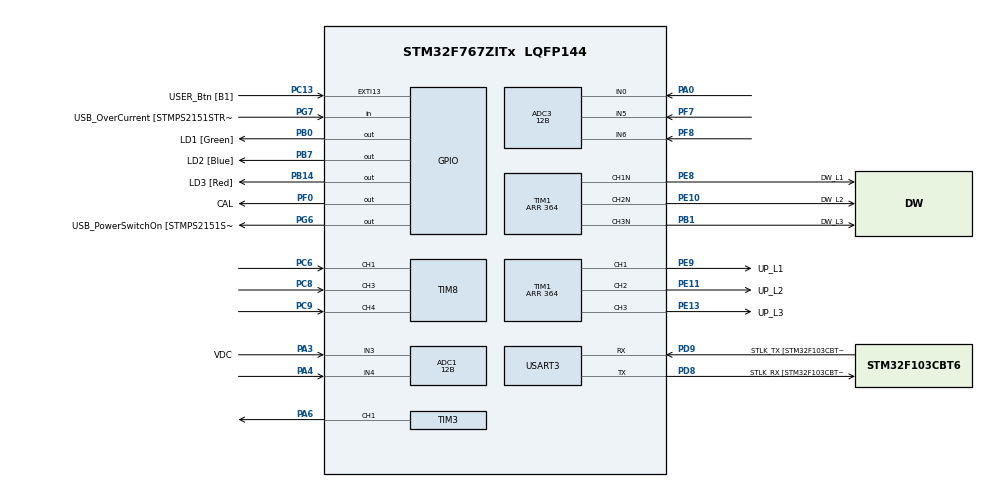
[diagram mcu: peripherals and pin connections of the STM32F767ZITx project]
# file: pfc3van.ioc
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ADC1.Channel-0\#ChannelRegularConversion=ADC_CHANNEL_3
ADC1.Channel-1\#ChannelRegularConversion=ADC_CHANNEL_4
ADC1.ClockPrescaler=ADC_CLOCK_SYNC_PCLK_DIV6
ADC1.ContinuousConvMode=ENABLE
ADC1.DMAContinuousRequests=ENABLE
ADC1.EOCSelection=ADC_EOC_SEQ_CONV
ADC1.EnableAnalogWatchDog=false
ADC1.ExternalTrigConv=ADC_SOFTWARE_START
ADC1.NbrOfConversion=2
ADC1.NbrOfConversionFlag=1
ADC1.Rank-0\#ChannelRegularConversion=1
ADC1.Rank-1\#ChannelRegularConversion=2
ADC1.Resolution=ADC_RESOLUTION_12B
ADC1.SamplingTime-0\#ChannelRegularConversion=ADC_SAMPLETIME_480CYCLES
ADC1.SamplingTime-1\#ChannelRegularConversion=ADC_SAMPLETIME_480CYCLES
ADC1.ScanConvMode=ADC_SCAN_ENABLE
ADC1.master=1
ADC3.Channel-1\#ChannelRegularConversion=ADC_CHANNEL_0
ADC3.Channel-10\#ChannelRegularConversion=ADC_CHANNEL_6
ADC3.Channel-9\#ChannelRegularConversion=ADC_CHANNEL_5
ADC3.ClockPrescaler=ADC_CLOCK_SYNC_PCLK_DIV6
ADC3.ContinuousConvMode=ENABLE
ADC3.DMAContinuousRequests=ENABLE
ADC3.DiscontinuousConvMode=DISABLE
ADC3.EOCSelection=ADC_EOC_SINGLE_CONV
ADC3.EnableAnalogWatchDog=false
ADC3.ExternalTrigConv=ADC_SOFTWARE_START
ADC3.NbrOfConversion=3
ADC3.NbrOfConversionFlag=1
ADC3.Rank-1\#ChannelRegularConversion=1
ADC3.Rank-10\#ChannelRegularConversion=3
ADC3.Rank-9\#ChannelRegularConversion=2
ADC3.Resolution=ADC_RESOLUTION_12B
ADC3.SamplingTime-1\#ChannelRegularConversion=ADC_SAMPLETIME_144CYCLES
ADC3.SamplingTime-10\#ChannelRegularConversion=ADC_SAMPLETIME_144CYCLES
ADC3.SamplingTime-9\#ChannelRegularConversion=ADC_SAMPLETIME_144CYCLES
ADC3.ScanConvMode=ADC_SCAN_ENABLE
CORTEX_M7.CPU_DCache=Enabled
CORTEX_M7.CPU_ICache=Enabled
CORTEX_M7.FlashInterface=TCM_Enabled
Dma.ADC1.1.Direction=DMA_PERIPH_TO_MEMORY
Dma.ADC1.1.FIFOMode=DMA_FIFOMODE_DISABLE
Dma.ADC1.1.Instance=DMA2_Stream0
Dma.ADC1.1.MemDataAlignment=DMA_MDATAALIGN_WORD
Dma.ADC1.1.MemInc=DMA_MINC_ENABLE
Dma.ADC1.1.Mode=DMA_CIRCULAR
Dma.ADC1.1.PeriphDataAlignment=DMA_PDATAALIGN_WORD
Dma.ADC1.1.PeriphInc=DMA_PINC_DISABLE
Dma.ADC1.1.Priority=DMA_PRIORITY_MEDIUM
Dma.ADC3.0.Direction=DMA_PERIPH_TO_MEMORY
Dma.ADC3.0.FIFOMode=DMA_FIFOMODE_DISABLE
Dma.ADC3.0.Instance=DMA2_Stream1
Dma.ADC3.0.MemDataAlignment=DMA_MDATAALIGN_WORD
Dma.ADC3.0.MemInc=DMA_MINC_ENABLE
Dma.ADC3.0.Mode=DMA_CIRCULAR
Dma.ADC3.0.PeriphDataAlignment=DMA_PDATAALIGN_WORD
Dma.ADC3.0.PeriphInc=DMA_PINC_DISABLE
Dma.ADC3.0.Priority=DMA_PRIORITY_VERY_HIGH
Dma.Request0=ADC3
Dma.Request1=ADC1
Dma.Request2=TIM8_CH1
Dma.Request3=TIM8_CH2
Dma.Request4=TIM8_CH3
Dma.Request5=TIM8_CH4/TRIG/COM
Dma.TIM8_CH1.2.Direction=DMA_PERIPH_TO_MEMORY
Dma.TIM8_CH1.2.FIFOMode=DMA_FIFOMODE_DISABLE
Dma.TIM8_CH1.2.Instance=DMA2_Stream2
Dma.TIM8_CH1.2.MemDataAlignment=DMA_MDATAALIGN_HALFWORD
Dma.TIM8_CH1.2.MemInc=DMA_MINC_ENABLE
Dma.TIM8_CH1.2.Mode=DMA_CIRCULAR
Dma.TIM8_CH1.2.PeriphDataAlignment=DMA_PDATAALIGN_HALFWORD
Dma.TIM8_CH1.2.PeriphInc=DMA_PINC_DISABLE
Dma.TIM8_CH1.2.Priority=DMA_PRIORITY_HIGH
Dma.TIM8_CH2.3.Direction=DMA_PERIPH_TO_MEMORY
Dma.TIM8_CH2.3.FIFOMode=DMA_FIFOMODE_DISABLE
Dma.TIM8_CH2.3.Instance=DMA2_Stream3
Dma.TIM8_CH2.3.MemDataAlignment=DMA_MDATAALIGN_HALFWORD
Dma.TIM8_CH2.3.MemInc=DMA_MINC_ENABLE
Dma.TIM8_CH2.3.Mode=DMA_CIRCULAR
Dma.TIM8_CH2.3.PeriphDataAlignment=DMA_PDATAALIGN_HALFWORD
Dma.TIM8_CH2.3.PeriphInc=DMA_PINC_DISABLE
Dma.TIM8_CH2.3.Priority=DMA_PRIORITY_HIGH
Dma.TIM8_CH3.4.Direction=DMA_PERIPH_TO_MEMORY
Dma.TIM8_CH3.4.FIFOMode=DMA_FIFOMODE_DISABLE
Dma.TIM8_CH3.4.Instance=DMA2_Stream4
Dma.TIM8_CH3.4.MemDataAlignment=DMA_MDATAALIGN_HALFWORD
Dma.TIM8_CH3.4.MemInc=DMA_MINC_ENABLE
Dma.TIM8_CH3.4.Mode=DMA_CIRCULAR
Dma.TIM8_CH3.4.PeriphDataAlignment=DMA_PDATAALIGN_HALFWORD
Dma.TIM8_CH3.4.PeriphInc=DMA_PINC_DISABLE
Dma.TIM8_CH3.4.Priority=DMA_PRIORITY_HIGH
Dma.TIM8_CH4/TRIG/COM.5.Direction=DMA_PERIPH_TO_MEMORY
Dma.TIM8_CH4/TRIG/COM.5.FIFOMode=DMA_FIFOMODE_DISABLE
Dma.TIM8_CH4/TRIG/COM.5.Instance=DMA2_Stream7
Dma.TIM8_CH4/TRIG/COM.5.MemDataAlignment=DMA_MDATAALIGN_HALFWORD
Dma.TIM8_CH4/TRIG/COM.5.MemInc=DMA_MINC_ENABLE
Dma.TIM8_CH4/TRIG/COM.5.Mode=DMA_CIRCULAR
Dma.TIM8_CH4/TRIG/COM.5.PeriphDataAlignment=DMA_PDATAALIGN_HALFWORD
Dma.TIM8_CH4/TRIG/COM.5.PeriphInc=DMA_PINC_DISABLE
Dma.TIM8_CH4/TRIG/COM.5.Priority=DMA_PRIORITY_HIGH
Mcu.Family=STM32F7
Mcu.Name=STM32F767ZITx
Mcu.Package=LQFP144
NVIC.DMA2_Stream0_IRQn=true\:6\:0\:true\:false\:true\:false\:true\:true
NVIC.DMA2_Stream1_IRQn=true\:6\:0\:false\:false\:true\:false\:true\:true
NVIC.DMA2_Stream2_IRQn=true\:6\:0\:true\:false\:true\:false\:true\:true
NVIC.DMA2_Stream3_IRQn=true\:6\:0\:true\:false\:true\:false\:true\:true
NVIC.DMA2_Stream4_IRQn=true\:6\:0\:true\:false\:true\:false\:true\:true
NVIC.DMA2_Stream7_IRQn=true\:6\:0\:true\:false\:true\:false\:true\:true
NVIC.EXTI15_10_IRQn=true\:15\:0\:true\:false\:true\:true\:true\:true
NVIC.PriorityGroup=NVIC_PRIORITYGROUP_4
NVIC.TIM1_CC_IRQn=true\:0\:0\:true\:false\:true\:true\:true\:true
NVIC.TIM1_TRG_COM_TIM11_IRQn=true\:0\:0\:false\:false\:true\:true\:true\:true
NVIC.TIM2_IRQn=true\:1\:0\:true\:false\:true\:true\:true\:true
NVIC.TIM5_IRQn=true\:15\:0\:true\:false\:true\:true\:true\:true
PA0/WKUP.Signal=ADCx_IN0
PA1.GPIO_Label=RMII_REF_CLK [LAN8742A-CZ-TR_REFCLK0]
PA1.Signal=ETH_REF_CLK
PA10.GPIO_Label=USB_ID
PA10.Signal=USB_OTG_FS_ID
PA11.GPIO_Label=USB_DM
PA11.Signal=USB_OTG_FS_DM
PA12.GPIO_Label=USB_DP
PA12.Signal=USB_OTG_FS_DP
PA13.GPIO_Label=TMS
PA13.Mode=Serial_Wire
PA13.Signal=SYS_JTMS-SWDIO
PA14.GPIO_Label=TCK
PA14.Mode=Serial_Wire
PA14.Signal=SYS_JTCK-SWCLK
PA2.GPIO_Label=RMII_MDIO [LAN8742A-CZ-TR_MDIO]
PA2.Signal=ETH_MDIO
PA3.GPIO_Label=VDC
PA3.Signal=ADCx_IN3
PA4.Signal=ADCx_IN4
PA6.Signal=S_TIM3_CH1
PA7.GPIO_Label=RMII_CRS_DV [LAN8742A-CZ-TR_CRS_DV]
PA7.Signal=ETH_CRS_DV
PA8.GPIO_Label=USB_SOF [TP1]
PA8.Signal=USB_OTG_FS_SOF
PA9.GPIO_Label=USB_VBUS
PA9.Signal=USB_OTG_FS_VBUS
PB0.GPIO_Label=LD1 [Green]
PB0.Signal=GPIO_Output
PB1.GPIO_Label=DW_L3
PB1.GPIO_PuPd=GPIO_PULLDOWN
PB1.GPIO_Speed=GPIO_SPEED_FREQ_HIGH
PB1.Mode=PWM Generation3 CH3 CH3N
PB1.Signal=TIM1_CH3N
PB13.GPIO_Label=RMII_TXD1 [LAN8742A-CZ-TR_TXD1]
PB13.Signal=ETH_TXD1
PB14.GPIO_Label=LD3 [Red]
PB14.Signal=GPIO_Output
PB3.GPIO_Label=SWO
PB3.Signal=SYS_JTDO-SWO
PB7.GPIO_Label=LD2 [Blue]
PB7.Signal=GPIO_Output
PC1.GPIO_Label=RMII_MDC [LAN8742A-CZ-TR_MDC]
PC1.Signal=ETH_MDC
PC13.GPIO_Label=USER_Btn [B1]
PC13.Signal=GPXTI13
PC14/OSC32_IN.Mode=LSE-External-Oscillator
PC14/OSC32_IN.Signal=RCC_OSC32_IN
PC15/OSC32_OUT.Mode=LSE-External-Oscillator
PC15/OSC32_OUT.Signal=RCC_OSC32_OUT
PC4.GPIO_Label=RMII_RXD0 [LAN8742A-CZ-TR_RXD0]
PC4.Signal=ETH_RXD0
PC5.GPIO_Label=RMII_RXD1 [LAN8742A-CZ-TR_RXD1]
PC5.Signal=ETH_RXD1
PC6.GPIO_Speed=GPIO_SPEED_FREQ_VERY_HIGH
PC6.Signal=S_TIM8_CH1
PC8.GPIO_Speed=GPIO_SPEED_FREQ_VERY_HIGH
PC8.Signal=S_TIM8_CH3
PC9.GPIO_Speed=GPIO_SPEED_FREQ_VERY_HIGH
PC9.Signal=S_TIM8_CH4
PD8.GPIO_Label=STLK_RX [STM32F103CBT6_PA3]
PD8.Mode=Asynchronous
PD8.Signal=USART3_TX
PD9.GPIO_Label=STLK_TX [STM32F103CBT6_PA2]
PD9.Mode=Asynchronous
PD9.Signal=USART3_RX
PE10.GPIO_Label=DW_L2
PE10.GPIO_ModeDefaultPP=GPIO_MODE_AF_PP
PE10.GPIO_PuPd=GPIO_PULLDOWN
PE10.GPIO_Speed=GPIO_SPEED_FREQ_HIGH
PE10.Mode=PWM Generation2 CH2 CH2N
PE10.Signal=TIM1_CH2N
PE11.GPIO_Label=UP_L2
PE11.GPIO_ModeDefaultPP=GPIO_MODE_AF_PP
PE11.GPIO_PuPd=GPIO_PULLDOWN
PE11.GPIO_Speed=GPIO_SPEED_FREQ_HIGH
PE11.Signal=S_TIM1_CH2
PE13.GPIO_Label=UP_L3
PE13.GPIO_ModeDefaultPP=GPIO_MODE_AF_PP
PE13.GPIO_PuPd=GPIO_PULLDOWN
PE13.GPIO_Speed=GPIO_SPEED_FREQ_HIGH
PE13.Signal=S_TIM1_CH3
PE8.GPIO_Label=DW_L1
PE8.GPIO_ModeDefaultPP=GPIO_MODE_AF_PP
PE8.GPIO_PuPd=GPIO_PULLDOWN
PE8.GPIO_Speed=GPIO_SPEED_FREQ_HIGH
PE8.Mode=PWM Generation1 CH1 CH1N
PE8.Signal=TIM1_CH1N
PE9.GPIO_Label=UP_L1
PE9.GPIO_ModeDefaultPP=GPIO_MODE_AF_PP
PE9.GPIO_PuPd=GPIO_PULLDOWN
PE9.GPIO_Speed=GPIO_SPEED_FREQ_HIGH
PE9.Signal=S_TIM1_CH1
PF0.GPIO_Label=CAL
PF0.GPIO_Speed=GPIO_SPEED_FREQ_VERY_HIGH
PF0.PinState=GPIO_PIN_RESET
PF0.Signal=GPIO_Output
PF7.Mode=IN5
PF7.Signal=ADC3_IN5
PF8.Mode=IN6
PF8.Signal=ADC3_IN6
PG11.GPIO_Label=RMII_TX_EN [LAN8742A-CZ-TR_TXEN]
PG11.Signal=ETH_TX_EN
PG13.GPIO_Label=RMII_TXD0 [LAN8742A-CZ-TR_TXD0]
PG13.Signal=ETH_TXD0
PG6.GPIO_Label=USB_PowerSwitchOn [STMPS2151STR_EN]
PG6.Signal=GPIO_Output
PG7.GPIO_Label=USB_OverCurrent [STMPS2151STR_FAULT]
PG7.Signal=GPIO_Input
PH0/OSC_IN.GPIO_Label=MCO [STM32F103CBT6_PA8]
PH0/OSC_IN.Mode=HSE-External-Clock-Source
PH0/OSC_IN.Signal=RCC_OSC_IN
PH1/OSC_OUT.Mode=HSE-External-Clock-Source
PH1/OSC_OUT.Signal=RCC_OSC_OUT
ProjectManager.HeapSize=0x200
ProjectManager.StackSize=0x400
ProjectManager.TargetToolchain=CMake
RCC.48MHZClocksFreq_Value=24000000
RCC.AHBFreq_Value=192000000
RCC.APB1CLKDivider=RCC_HCLK_DIV4
RCC.APB1Freq_Value=48000000
RCC.APB1TimFreq_Value=96000000
RCC.APB2CLKDivider=RCC_HCLK_DIV2
RCC.APB2Freq_Value=96000000
RCC.APB2TimFreq_Value=192000000
RCC.CortexFreq_Value=192000000
RCC.HCLKFreq_Value=192000000
RCC.HSE_VALUE=32000000
RCC.HSI_VALUE=16000000
RCC.PLLMUL=RCC_PLL_MUL9
RCC.PLLQ=4
RCC.PLLSourceVirtual=RCC_PLLSOURCE_HSE
RCC.PRESCALERUSB=RCC_USBCLKSOURCE_PLL_DIV1_5
RCC.SYSCLKFreq_VALUE=192000000
RCC.SYSCLKSource=RCC_SYSCLKSOURCE_PLLCLK
RCC.SYSCLKSourceVirtual=RCC_SYSCLKSOURCE_PLLCLK
RCC.USBFreq_Value=96000000
RCC.VCOOutputFreq_Value=384000000
SH.ADCx_IN0.0=ADC3_IN0,IN0
SH.ADCx_IN3.0=ADC1_IN3,IN3
SH.ADCx_IN4.0=ADC1_IN4,IN4
SH.S_TIM1_CH1.0=TIM1_CH1,PWM Generation1 CH1 CH1N
SH.S_TIM1_CH2.0=TIM1_CH2,PWM Generation2 CH2 CH2N
SH.S_TIM1_CH3.0=TIM1_CH3,PWM Generation3 CH3 CH3N
SH.S_TIM3_CH1.0=TIM3_CH1,Forced Output1 CH1
SH.S_TIM8_CH1.0=TIM8_CH1,Input_Capture1_from_TI1
SH.S_TIM8_CH1.1=TIM8_CH1,TriggerSource_TI1FP1
SH.S_TIM8_CH3.0=TIM8_CH3,Input_Capture3_from_TI3
SH.S_TIM8_CH4.0=TIM8_CH4,Input_Capture4_from_TI4
TIM1.AutoReloadPreload=TIM_AUTORELOAD_PRELOAD_ENABLE
TIM1.AutomaticOutput=TIM_AUTOMATICOUTPUT_DISABLE
TIM1.Break2State=TIM_BREAK2_ENABLE
TIM1.BreakState=TIM_BREAK_DISABLE
TIM1.Channel-PWM\ Generation1\ CH1\ CH1N=TIM_CHANNEL_1
TIM1.Channel-PWM\ Generation2\ CH2\ CH2N=TIM_CHANNEL_2
TIM1.Channel-PWM\ Generation3\ CH3\ CH3N=TIM_CHANNEL_3
TIM1.CounterMode=TIM_COUNTERMODE_CENTERALIGNED1
TIM1.DeadTime=19
TIM1.OCFastMode_PWM-PWM\ Generation1\ CH1\ CH1N=TIM_OCFAST_DISABLE
TIM1.OCIdleState_1=TIM_OCIDLESTATE_RESET
TIM1.OCMode_PWM-PWM\ Generation1\ CH1\ CH1N=TIM_OCMODE_PWM2
TIM1.OCMode_PWM-PWM\ Generation2\ CH2\ CH2N=TIM_OCMODE_PWM2
TIM1.OCMode_PWM-PWM\ Generation3\ CH3\ CH3N=TIM_OCMODE_PWM2
TIM1.OCNIdleState_1=TIM_OCNIDLESTATE_RESET
TIM1.OCNIdleState_2=TIM_OCNIDLESTATE_RESET
TIM1.OCNPolarity_1=TIM_OCNPOLARITY_HIGH
TIM1.OCNPolarity_2=TIM_OCNPOLARITY_HIGH
TIM1.OCPolarity_1=TIM_OCPOLARITY_HIGH
TIM1.OffStateIDLEMode=TIM_OSSI_ENABLE
TIM1.OffStateRunMode=TIM_OSSR_ENABLE
TIM1.Period=364
TIM1.Pulse-PWM\ Generation1\ CH1\ CH1N=300
TIM1.Pulse-PWM\ Generation2\ CH2\ CH2N=600
TIM1.Pulse-PWM\ Generation3\ CH3\ CH3N=200
TIM1.RepetitionCounter=0
TIM1.TIM_MasterOutputTrigger=TIM_TRGO_UPDATE
TIM1.TIM_MasterOutputTrigger2=TIM_TRGO2_RESET
TIM1.TIM_MasterSlaveMode=TIM_MASTERSLAVEMODE_DISABLE
TIM11.Period=65535
TIM2.Period=3000
TIM3.Channel-Forced\ Output1\ CH1=TIM_CHANNEL_1
TIM3.TIM_MasterOutputTrigger=TIM_TRGO_ENABLE
TIM3.TIM_MasterSlaveMode=TIM_MASTERSLAVEMODE_ENABLE
TIM5.Period=4294967295
TIM8.Channel-Input_Capture1_from_TI1=TIM_CHANNEL_1
TIM8.Channel-Input_Capture2_from_TI1_63=TIM_CHANNEL_2
TIM8.Channel-Input_Capture3_from_TI3=TIM_CHANNEL_3
TIM8.Channel-Input_Capture4_from_TI4=TIM_CHANNEL_4
TIM8.ICFilter_CH1=10
TIM8.ICFilter_CH3=10
TIM8.ICFilter_CH4=10
TIM8.ICPolarity_CH1=TIM_INPUTCHANNELPOLARITY_RISING
TIM8.ICPolarity_CH2=TIM_INPUTCHANNELPOLARITY_FALLING
TIM8.ICPolarity_CH3=TIM_INPUTCHANNELPOLARITY_FALLING
TIM8.ICPolarity_CH4=TIM_INPUTCHANNELPOLARITY_FALLING
USART3.VirtualMode-Asynchronous=VM_ASYNC
VP_TIM11_VS_ClockSourceINT.Mode=Enable_Timer
VP_TIM1_VS_ClockSourceINT.Mode=Internal
VP_TIM2_VS_ClockSourceINT.Mode=Internal
VP_TIM3_VS_ClockSourceINT.Mode=Internal
VP_TIM5_VS_ClockSourceINT.Mode=Internal
VP_TIM8_VS_ClockSourceINT.Mode=Internal
VP_TIM8_VS_ControllerModeReset.Mode=Reset Mode
VP_TIM8_VS_indirect_ch1.Mode=Input_Capture2_from_TI1_63
board=NUCLEO-F767ZI

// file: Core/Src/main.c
/* USER CODE BEGIN Header */
/**
 ******************************************************************************
 * @file           : main.c
 * @brief          : Main program body
 ******************************************************************************
 * @attention
 *
 * Copyright (c) 2025 STMicroelectronics.
 * All rights reserved.
 *
 * This software is licensed under terms that can be found in the LICENSE file
 * in the root directory of this software component.
 * If no LICENSE file comes with this software, it is provided AS-IS.
 *
 ******************************************************************************
 */
/* USER CODE END Header */
#include "main.h"

/* USER CODE BEGIN PV */
#define CTRL_ON 1
#define CTRL_OFF 0
#define VAC_LENGTH 1
int8_t CTRL_STATE = CTRL_OFF;

/* USER CODE END PV */

void SystemClock_Config(void);
static void MX_GPIO_Init(void);
static void MX_DMA_Init(void);
static void MX_ADC3_Init(void);
static void MX_USART3_UART_Init(void);
static void MX_ADC1_Init(void);
static void MX_TIM1_Init(void);
static void MX_TIM3_Init(void);
static void MX_TIM2_Init(void);
static void MX_TIM11_Init(void);
static void MX_TIM8_Init(void);
static void MX_TIM5_Init(void);

/* USER CODE BEGIN 0 */
static void Init_Ctrl(void);
uint32_t iac_data[3], dc_data[2], vac_data[1], vac_1_data[1];
uint32_t vacs[4];
/* USER CODE END 0 */

int main(void) {

  /* Enable the CPU Cache */

  /* Enable I-Cache---------------------------------------------------------*/
  SCB_EnableICache();

  /* Enable D-Cache---------------------------------------------------------*/
  SCB_EnableDCache();

  /* MCU Configuration--------------------------------------------------------*/

  /* Reset of all peripherals, Initializes the Flash interface and the Systick.
   */
  LL_APB1_GRP1_EnableClock(LL_APB1_GRP1_PERIPH_PWR);
  LL_APB2_GRP1_EnableClock(LL_APB2_GRP1_PERIPH_SYSCFG);

  /* System interrupt init*/
  NVIC_SetPriorityGrouping(NVIC_PRIORITYGROUP_4);

  /* MemoryManagement_IRQn interrupt configuration */
  NVIC_SetPriority(MemoryManagement_IRQn,
                   NVIC_EncodePriority(NVIC_GetPriorityGrouping(), 4, 0));
  /* BusFault_IRQn interrupt configuration */
  NVIC_SetPriority(BusFault_IRQn,
                   NVIC_EncodePriority(NVIC_GetPriorityGrouping(), 4, 0));
  /* UsageFault_IRQn interrupt configuration */
  NVIC_SetPriority(UsageFault_IRQn,
                   NVIC_EncodePriority(NVIC_GetPriorityGrouping(), 4, 0));
  /* SVCall_IRQn interrupt configuration */
  NVIC_SetPriority(SVCall_IRQn,
                   NVIC_EncodePriority(NVIC_GetPriorityGrouping(), 4, 0));
  /* DebugMonitor_IRQn interrupt configuration */
  NVIC_SetPriority(DebugMonitor_IRQn,
                   NVIC_EncodePriority(NVIC_GetPriorityGrouping(), 4, 0));
  /* PendSV_IRQn interrupt configuration */
  NVIC_SetPriority(PendSV_IRQn,
                   NVIC_EncodePriority(NVIC_GetPriorityGrouping(), 4, 0));

  /* Configure the system clock */
  SystemClock_Config();

  /* Initialize all configured peripherals */
  MX_GPIO_Init();
  MX_DMA_Init();
  MX_ADC3_Init();
  MX_USART3_UART_Init();
  MX_ADC1_Init();
  MX_TIM1_Init();
  MX_TIM3_Init();
  MX_TIM2_Init();
  MX_TIM11_Init();
  MX_TIM8_Init();
  MX_TIM5_Init();
  /* USER CODE BEGIN 2 */
  Init_Ctrl();

  /* USER CODE END 2 */

  /* Infinite loop */
  while (1) {

  }
}

void SystemClock_Config(void) {
  LL_FLASH_SetLatency(LL_FLASH_LATENCY_6);
  while (LL_FLASH_GetLatency() != LL_FLASH_LATENCY_6) {
  }
  LL_PWR_SetRegulVoltageScaling(LL_PWR_REGU_VOLTAGE_SCALE1);
  LL_PWR_EnableOverDriveMode();
  LL_RCC_HSE_EnableBypass();
  LL_RCC_HSE_Enable();

  /* Wait till HSE is ready */
  while (LL_RCC_HSE_IsReady() != 1) {
  }
  LL_RCC_PLL_ConfigDomain_SYS(LL_RCC_PLLSOURCE_HSE, LL_RCC_PLLM_DIV_16, 192,
                              LL_RCC_PLLP_DIV_2);
  LL_RCC_PLL_Enable();

  /* Wait till PLL is ready */
  while (LL_RCC_PLL_IsReady() != 1) {
  }
  while (LL_PWR_IsActiveFlag_VOS() == 0) {
  }
  LL_RCC_SetAHBPrescaler(LL_RCC_SYSCLK_DIV_1);
  LL_RCC_SetAPB1Prescaler(LL_RCC_APB1_DIV_4);
  LL_RCC_SetAPB2Prescaler(LL_RCC_APB2_DIV_2);
  LL_RCC_SetSysClkSource(LL_RCC_SYS_CLKSOURCE_PLL);

  /* Wait till System clock is ready */
  while (LL_RCC_GetSysClkSource() != LL_RCC_SYS_CLKSOURCE_STATUS_PLL) {
  }
  LL_Init1msTick(192000000);
  LL_SetSystemCoreClock(192000000);

  /* Set Timers Clock Prescalers */
  LL_RCC_SetTIMPrescaler(LL_RCC_TIM_PRESCALER_TWICE);
}

static void MX_ADC1_Init(void) {

  LL_ADC_InitTypeDef ADC_InitStruct = {0};
  LL_ADC_REG_InitTypeDef ADC_REG_InitStruct = {0};
  LL_ADC_CommonInitTypeDef ADC_CommonInitStruct = {0};

  LL_GPIO_InitTypeDef GPIO_InitStruct = {0};

  /* Peripheral clock enable */
  LL_APB2_GRP1_EnableClock(LL_APB2_GRP1_PERIPH_ADC1);

  LL_AHB1_GRP1_EnableClock(LL_AHB1_GRP1_PERIPH_GPIOA);
  /**ADC1 GPIO Configuration
  PA3   ------> ADC1_IN3
  PA4   ------> ADC1_IN4
  */
  GPIO_InitStruct.Pin = VDC_Pin;
  GPIO_InitStruct.Mode = LL_GPIO_MODE_ANALOG;
  GPIO_InitStruct.Pull = LL_GPIO_PULL_NO;
  LL_GPIO_Init(VDC_GPIO_Port, &GPIO_InitStruct);

  GPIO_InitStruct.Pin = LL_GPIO_PIN_4;
  GPIO_InitStruct.Mode = LL_GPIO_MODE_ANALOG;
  GPIO_InitStruct.Pull = LL_GPIO_PULL_NO;
  LL_GPIO_Init(GPIOA, &GPIO_InitStruct);

  /* ADC1 DMA Init */

  /* ADC1 Init */
  LL_DMA_SetChannelSelection(DMA2, LL_DMA_STREAM_0, LL_DMA_CHANNEL_0);

  LL_DMA_SetDataTransferDirection(DMA2, LL_DMA_STREAM_0,
                                  LL_DMA_DIRECTION_PERIPH_TO_MEMORY);

  LL_DMA_SetStreamPriorityLevel(DMA2, LL_DMA_STREAM_0, LL_DMA_PRIORITY_MEDIUM);

  LL_DMA_SetMode(DMA2, LL_DMA_STREAM_0, LL_DMA_MODE_CIRCULAR);

  LL_DMA_SetPeriphIncMode(DMA2, LL_DMA_STREAM_0, LL_DMA_PERIPH_NOINCREMENT);

  LL_DMA_SetMemoryIncMode(DMA2, LL_DMA_STREAM_0, LL_DMA_MEMORY_INCREMENT);

  LL_DMA_SetPeriphSize(DMA2, LL_DMA_STREAM_0, LL_DMA_PDATAALIGN_WORD);

  LL_DMA_SetMemorySize(DMA2, LL_DMA_STREAM_0, LL_DMA_MDATAALIGN_WORD);

  LL_DMA_DisableFifoMode(DMA2, LL_DMA_STREAM_0);

  /** Common config
   */
  ADC_InitStruct.Resolution = LL_ADC_RESOLUTION_12B;
  ADC_InitStruct.DataAlignment = LL_ADC_DATA_ALIGN_RIGHT;
  ADC_InitStruct.SequencersScanMode = LL_ADC_SEQ_SCAN_ENABLE;
  LL_ADC_Init(ADC1, &ADC_InitStruct);
  ADC_REG_InitStruct.TriggerSource = LL_ADC_REG_TRIG_SOFTWARE;
  ADC_REG_InitStruct.SequencerLength = LL_ADC_REG_SEQ_SCAN_ENABLE_2RANKS;
  ADC_REG_InitStruct.SequencerDiscont = LL_ADC_REG_SEQ_DISCONT_DISABLE;
  ADC_REG_InitStruct.ContinuousMode = LL_ADC_REG_CONV_CONTINUOUS;
  ADC_REG_InitStruct.DMATransfer = LL_ADC_REG_DMA_TRANSFER_UNLIMITED;
  LL_ADC_REG_Init(ADC1, &ADC_REG_InitStruct);
  LL_ADC_REG_SetFlagEndOfConversion(ADC1, LL_ADC_REG_FLAG_EOC_SEQUENCE_CONV);
  ADC_CommonInitStruct.CommonClock = LL_ADC_CLOCK_SYNC_PCLK_DIV6;
  ADC_CommonInitStruct.Multimode = LL_ADC_MULTI_INDEPENDENT;
  LL_ADC_CommonInit(__LL_ADC_COMMON_INSTANCE(ADC1), &ADC_CommonInitStruct);

  /** Configure Regular Channel
   */
  LL_ADC_REG_SetSequencerRanks(ADC1, LL_ADC_REG_RANK_1, LL_ADC_CHANNEL_3);
  LL_ADC_SetChannelSamplingTime(ADC1, LL_ADC_CHANNEL_3,
                                LL_ADC_SAMPLINGTIME_480CYCLES);

  /** Configure Regular Channel
   */
  LL_ADC_REG_SetSequencerRanks(ADC1, LL_ADC_REG_RANK_2, LL_ADC_CHANNEL_4);
  LL_ADC_SetChannelSamplingTime(ADC1, LL_ADC_CHANNEL_4,
                                LL_ADC_SAMPLINGTIME_480CYCLES);
  /* USER CODE BEGIN ADC1_Init 2 */
  LL_DMA_ConfigAddresses(
      DMA2, LL_DMA_STREAM_0,
      LL_ADC_DMA_GetRegAddr(ADC1, LL_ADC_DMA_REG_REGULAR_DATA),
      (uint32_t)&dc_data, LL_DMA_DIRECTION_PERIPH_TO_MEMORY);
  LL_DMA_SetDataLength(DMA2, LL_DMA_STREAM_0, (uint32_t)2);

  /* Enable DMA transfer interruption: transfer complete */
  LL_DMA_EnableIT_TC(DMA2, LL_DMA_STREAM_0);

  /* Enable DMA transfer interruption: half transfer */

  /* Enable DMA transfer interruption: transfer error */
  LL_DMA_EnableIT_TE(DMA2, LL_DMA_STREAM_0);
  LL_DMA_EnableStream(DMA2, LL_DMA_STREAM_0);
  /* USER CODE END ADC1_Init 2 */
}

static void MX_ADC3_Init(void) {

  LL_ADC_InitTypeDef ADC_InitStruct = {0};
  LL_ADC_REG_InitTypeDef ADC_REG_InitStruct = {0};

  LL_GPIO_InitTypeDef GPIO_InitStruct = {0};

  /* Peripheral clock enable */
  LL_APB2_GRP1_EnableClock(LL_APB2_GRP1_PERIPH_ADC3);

  LL_AHB1_GRP1_EnableClock(LL_AHB1_GRP1_PERIPH_GPIOF);
  LL_AHB1_GRP1_EnableClock(LL_AHB1_GRP1_PERIPH_GPIOA);
  /**ADC3 GPIO Configuration
  PF7   ------> ADC3_IN5
  PF8   ------> ADC3_IN6
  PA0/WKUP   ------> ADC3_IN0
  */
  GPIO_InitStruct.Pin = LL_GPIO_PIN_7;
  GPIO_InitStruct.Mode = LL_GPIO_MODE_ANALOG;
  GPIO_InitStruct.Pull = LL_GPIO_PULL_NO;
  LL_GPIO_Init(GPIOF, &GPIO_InitStruct);

  GPIO_InitStruct.Pin = LL_GPIO_PIN_8;
  GPIO_InitStruct.Mode = LL_GPIO_MODE_ANALOG;
  GPIO_InitStruct.Pull = LL_GPIO_PULL_NO;
  LL_GPIO_Init(GPIOF, &GPIO_InitStruct);

  GPIO_InitStruct.Pin = LL_GPIO_PIN_0;
  GPIO_InitStruct.Mode = LL_GPIO_MODE_ANALOG;
  GPIO_InitStruct.Pull = LL_GPIO_PULL_NO;
  LL_GPIO_Init(GPIOA, &GPIO_InitStruct);

  /* ADC3 DMA Init */

  /* ADC3 Init */
  LL_DMA_SetChannelSelection(DMA2, LL_DMA_STREAM_1, LL_DMA_CHANNEL_2);

  LL_DMA_SetDataTransferDirection(DMA2, LL_DMA_STREAM_1,
                                  LL_DMA_DIRECTION_PERIPH_TO_MEMORY);

  LL_DMA_SetStreamPriorityLevel(DMA2, LL_DMA_STREAM_1,
                                LL_DMA_PRIORITY_VERYHIGH);

  LL_DMA_SetMode(DMA2, LL_DMA_STREAM_1, LL_DMA_MODE_CIRCULAR);

  LL_DMA_SetPeriphIncMode(DMA2, LL_DMA_STREAM_1, LL_DMA_PERIPH_NOINCREMENT);

  LL_DMA_SetMemoryIncMode(DMA2, LL_DMA_STREAM_1, LL_DMA_MEMORY_INCREMENT);

  LL_DMA_SetPeriphSize(DMA2, LL_DMA_STREAM_1, LL_DMA_PDATAALIGN_WORD);

  LL_DMA_SetMemorySize(DMA2, LL_DMA_STREAM_1, LL_DMA_MDATAALIGN_WORD);

  LL_DMA_DisableFifoMode(DMA2, LL_DMA_STREAM_1);

  /* USER CODE BEGIN ADC3_Init 1 */
  LL_DMA_ConfigAddresses(
      DMA2, LL_DMA_STREAM_1,
      LL_ADC_DMA_GetRegAddr(ADC3, LL_ADC_DMA_REG_REGULAR_DATA),
      (uint32_t)&iac_data, LL_DMA_DIRECTION_PERIPH_TO_MEMORY);
  LL_DMA_SetDataLength(DMA2, LL_DMA_STREAM_1, (uint32_t)3);

  /* Enable DMA transfer interruption: transfer complete */
  LL_DMA_EnableIT_TC(DMA2, LL_DMA_STREAM_1);

  /* Enable DMA transfer interruption: half transfer */

  /* Enable DMA transfer interruption: transfer error */
  LL_DMA_EnableIT_TE(DMA2, LL_DMA_STREAM_1);
  LL_DMA_EnableStream(DMA2, LL_DMA_STREAM_1);
  /* USER CODE END ADC3_Init 1 */

  /** Common config
   */
  ADC_InitStruct.Resolution = LL_ADC_RESOLUTION_12B;
  ADC_InitStruct.DataAlignment = LL_ADC_DATA_ALIGN_RIGHT;
  ADC_InitStruct.SequencersScanMode = LL_ADC_SEQ_SCAN_ENABLE;
  LL_ADC_Init(ADC3, &ADC_InitStruct);
  ADC_REG_InitStruct.TriggerSource = LL_ADC_REG_TRIG_SOFTWARE;
  ADC_REG_InitStruct.SequencerLength = LL_ADC_REG_SEQ_SCAN_ENABLE_3RANKS;
  ADC_REG_InitStruct.SequencerDiscont = LL_ADC_REG_SEQ_DISCONT_DISABLE;
  ADC_REG_InitStruct.ContinuousMode = LL_ADC_REG_CONV_CONTINUOUS;
  ADC_REG_InitStruct.DMATransfer = LL_ADC_REG_DMA_TRANSFER_UNLIMITED;
  LL_ADC_REG_Init(ADC3, &ADC_REG_InitStruct);
  LL_ADC_REG_SetFlagEndOfConversion(ADC3, LL_ADC_REG_FLAG_EOC_UNITARY_CONV);

  /** Configure Regular Channel
   */
  LL_ADC_REG_SetSequencerRanks(ADC3, LL_ADC_REG_RANK_1, LL_ADC_CHANNEL_0);
  LL_ADC_SetChannelSamplingTime(ADC3, LL_ADC_CHANNEL_0,
                                LL_ADC_SAMPLINGTIME_144CYCLES);

  /** Configure Regular Channel
   */
  LL_ADC_REG_SetSequencerRanks(ADC3, LL_ADC_REG_RANK_2, LL_ADC_CHANNEL_5);
  LL_ADC_SetChannelSamplingTime(ADC3, LL_ADC_CHANNEL_5,
                                LL_ADC_SAMPLINGTIME_144CYCLES);

  /** Configure Regular Channel
   */
  LL_ADC_REG_SetSequencerRanks(ADC3, LL_ADC_REG_RANK_3, LL_ADC_CHANNEL_6);
  LL_ADC_SetChannelSamplingTime(ADC3, LL_ADC_CHANNEL_6,
                                LL_ADC_SAMPLINGTIME_144CYCLES);
}

static void MX_TIM1_Init(void) {

  LL_TIM_InitTypeDef TIM_InitStruct = {0};
  LL_TIM_OC_InitTypeDef TIM_OC_InitStruct = {0};
  LL_TIM_BDTR_InitTypeDef TIM_BDTRInitStruct = {0};

  LL_GPIO_InitTypeDef GPIO_InitStruct = {0};

  /* Peripheral clock enable */
  LL_APB2_GRP1_EnableClock(LL_APB2_GRP1_PERIPH_TIM1);

  /* TIM1 interrupt Init */
  NVIC_SetPriority(TIM1_TRG_COM_TIM11_IRQn,
                   NVIC_EncodePriority(NVIC_GetPriorityGrouping(), 0, 0));
  NVIC_EnableIRQ(TIM1_TRG_COM_TIM11_IRQn);
  NVIC_SetPriority(TIM1_CC_IRQn,
                   NVIC_EncodePriority(NVIC_GetPriorityGrouping(), 0, 0));
  NVIC_EnableIRQ(TIM1_CC_IRQn);

  TIM_InitStruct.Prescaler = 0;
  TIM_InitStruct.CounterMode = LL_TIM_COUNTERMODE_CENTER_DOWN;
  TIM_InitStruct.Autoreload = 364;
  TIM_InitStruct.ClockDivision = LL_TIM_CLOCKDIVISION_DIV1;
  TIM_InitStruct.RepetitionCounter = 0;
  LL_TIM_Init(TIM1, &TIM_InitStruct);
  LL_TIM_EnableARRPreload(TIM1);
  LL_TIM_SetClockSource(TIM1, LL_TIM_CLOCKSOURCE_INTERNAL);
  LL_TIM_OC_EnablePreload(TIM1, LL_TIM_CHANNEL_CH1);
  TIM_OC_InitStruct.OCMode = LL_TIM_OCMODE_PWM2;
  TIM_OC_InitStruct.OCState = LL_TIM_OCSTATE_DISABLE;
  TIM_OC_InitStruct.OCNState = LL_TIM_OCSTATE_DISABLE;
  TIM_OC_InitStruct.CompareValue = 300;
  TIM_OC_InitStruct.OCPolarity = LL_TIM_OCPOLARITY_HIGH;
  TIM_OC_InitStruct.OCNPolarity = LL_TIM_OCPOLARITY_HIGH;
  TIM_OC_InitStruct.OCIdleState = LL_TIM_OCIDLESTATE_LOW;
  TIM_OC_InitStruct.OCNIdleState = LL_TIM_OCIDLESTATE_LOW;
  LL_TIM_OC_Init(TIM1, LL_TIM_CHANNEL_CH1, &TIM_OC_InitStruct);
  LL_TIM_OC_DisableFast(TIM1, LL_TIM_CHANNEL_CH1);
  LL_TIM_OC_EnablePreload(TIM1, LL_TIM_CHANNEL_CH2);
  TIM_OC_InitStruct.CompareValue = 600;
  LL_TIM_OC_Init(TIM1, LL_TIM_CHANNEL_CH2, &TIM_OC_InitStruct);
  LL_TIM_OC_DisableFast(TIM1, LL_TIM_CHANNEL_CH2);
  LL_TIM_OC_EnablePreload(TIM1, LL_TIM_CHANNEL_CH3);
  TIM_OC_InitStruct.CompareValue = 200;
  LL_TIM_OC_Init(TIM1, LL_TIM_CHANNEL_CH3, &TIM_OC_InitStruct);
  LL_TIM_OC_DisableFast(TIM1, LL_TIM_CHANNEL_CH3);
  LL_TIM_SetTriggerOutput(TIM1, LL_TIM_TRGO_UPDATE);
  LL_TIM_SetTriggerOutput2(TIM1, LL_TIM_TRGO2_RESET);
  LL_TIM_DisableMasterSlaveMode(TIM1);
  TIM_BDTRInitStruct.OSSRState = LL_TIM_OSSR_ENABLE;
  TIM_BDTRInitStruct.OSSIState = LL_TIM_OSSI_ENABLE;
  TIM_BDTRInitStruct.LockLevel = LL_TIM_LOCKLEVEL_OFF;
  TIM_BDTRInitStruct.DeadTime = 19;
  TIM_BDTRInitStruct.BreakState = LL_TIM_BREAK_DISABLE;
  TIM_BDTRInitStruct.BreakPolarity = LL_TIM_BREAK_POLARITY_HIGH;
  TIM_BDTRInitStruct.BreakFilter = LL_TIM_BREAK_FILTER_FDIV1;
  TIM_BDTRInitStruct.Break2State = LL_TIM_BREAK2_ENABLE;
  TIM_BDTRInitStruct.Break2Polarity = LL_TIM_BREAK2_POLARITY_HIGH;
  TIM_BDTRInitStruct.Break2Filter = LL_TIM_BREAK2_FILTER_FDIV1;
  TIM_BDTRInitStruct.AutomaticOutput = LL_TIM_AUTOMATICOUTPUT_DISABLE;
  LL_TIM_BDTR_Init(TIM1, &TIM_BDTRInitStruct);
  /* USER CODE BEGIN TIM1_Init 2 */
  /*sConfigOC.OCMode = TIM_OCMODE_COMBINED_PWM1;
   if (HAL_TIM_OC_ConfigChannel(&htim1, &sConfigOC, TIM_CHANNEL_3) != HAL_OK)
  {
    Error_Handler();
  }*/

  /* USER CODE END TIM1_Init 2 */
  LL_AHB1_GRP1_EnableClock(LL_AHB1_GRP1_PERIPH_GPIOB);
  LL_AHB1_GRP1_EnableClock(LL_AHB1_GRP1_PERIPH_GPIOE);
  /**TIM1 GPIO Configuration
  PB1   ------> TIM1_CH3N
  PE8   ------> TIM1_CH1N
  PE9   ------> TIM1_CH1
  PE10   ------> TIM1_CH2N
  PE11   ------> TIM1_CH2
  PE13   ------> TIM1_CH3
  */
  GPIO_InitStruct.Pin = DW_L3_Pin;
  GPIO_InitStruct.Mode = LL_GPIO_MODE_ALTERNATE;
  GPIO_InitStruct.Speed = LL_GPIO_SPEED_FREQ_HIGH;
  GPIO_InitStruct.OutputType = LL_GPIO_OUTPUT_PUSHPULL;
  GPIO_InitStruct.Pull = LL_GPIO_PULL_DOWN;
  GPIO_InitStruct.Alternate = LL_GPIO_AF_1;
  LL_GPIO_Init(DW_L3_GPIO_Port, &GPIO_InitStruct);

  GPIO_InitStruct.Pin = DW_L1_Pin;
  GPIO_InitStruct.Mode = LL_GPIO_MODE_ALTERNATE;
  GPIO_InitStruct.Speed = LL_GPIO_SPEED_FREQ_HIGH;
  GPIO_InitStruct.OutputType = LL_GPIO_OUTPUT_PUSHPULL;
  GPIO_InitStruct.Pull = LL_GPIO_PULL_DOWN;
  GPIO_InitStruct.Alternate = LL_GPIO_AF_1;
  LL_GPIO_Init(DW_L1_GPIO_Port, &GPIO_InitStruct);

  GPIO_InitStruct.Pin = UP_L1_Pin;
  GPIO_InitStruct.Mode = LL_GPIO_MODE_ALTERNATE;
  GPIO_InitStruct.Speed = LL_GPIO_SPEED_FREQ_HIGH;
  GPIO_InitStruct.OutputType = LL_GPIO_OUTPUT_PUSHPULL;
  GPIO_InitStruct.Pull = LL_GPIO_PULL_DOWN;
  GPIO_InitStruct.Alternate = LL_GPIO_AF_1;
  LL_GPIO_Init(UP_L1_GPIO_Port, &GPIO_InitStruct);

  GPIO_InitStruct.Pin = DW_L2_Pin;
  GPIO_InitStruct.Mode = LL_GPIO_MODE_ALTERNATE;
  GPIO_InitStruct.Speed = LL_GPIO_SPEED_FREQ_HIGH;
  GPIO_InitStruct.OutputType = LL_GPIO_OUTPUT_PUSHPULL;
  GPIO_InitStruct.Pull = LL_GPIO_PULL_DOWN;
  GPIO_InitStruct.Alternate = LL_GPIO_AF_1;
  LL_GPIO_Init(DW_L2_GPIO_Port, &GPIO_InitStruct);

  GPIO_InitStruct.Pin = UP_L2_Pin;
  GPIO_InitStruct.Mode = LL_GPIO_MODE_ALTERNATE;
  GPIO_InitStruct.Speed = LL_GPIO_SPEED_FREQ_HIGH;
  GPIO_InitStruct.OutputType = LL_GPIO_OUTPUT_PUSHPULL;
  GPIO_InitStruct.Pull = LL_GPIO_PULL_DOWN;
  GPIO_InitStruct.Alternate = LL_GPIO_AF_1;
  LL_GPIO_Init(UP_L2_GPIO_Port, &GPIO_InitStruct);

  GPIO_InitStruct.Pin = UP_L3_Pin;
  GPIO_InitStruct.Mode = LL_GPIO_MODE_ALTERNATE;
  GPIO_InitStruct.Speed = LL_GPIO_SPEED_FREQ_HIGH;
  GPIO_InitStruct.OutputType = LL_GPIO_OUTPUT_PUSHPULL;
  GPIO_InitStruct.Pull = LL_GPIO_PULL_DOWN;
  GPIO_InitStruct.Alternate = LL_GPIO_AF_1;
  LL_GPIO_Init(UP_L3_GPIO_Port, &GPIO_InitStruct);
}

static void MX_TIM2_Init(void) {

  LL_TIM_InitTypeDef TIM_InitStruct = {0};

  /* Peripheral clock enable */
  LL_APB1_GRP1_EnableClock(LL_APB1_GRP1_PERIPH_TIM2);

  /* TIM2 interrupt Init */
  NVIC_SetPriority(TIM2_IRQn,
                   NVIC_EncodePriority(NVIC_GetPriorityGrouping(), 1, 0));
  NVIC_EnableIRQ(TIM2_IRQn);

  TIM_InitStruct.Prescaler = 0;
  TIM_InitStruct.CounterMode = LL_TIM_COUNTERMODE_UP;
  TIM_InitStruct.Autoreload = 3000;
  TIM_InitStruct.ClockDivision = LL_TIM_CLOCKDIVISION_DIV1;
  LL_TIM_Init(TIM2, &TIM_InitStruct);
  LL_TIM_DisableARRPreload(TIM2);
  LL_TIM_SetClockSource(TIM2, LL_TIM_CLOCKSOURCE_INTERNAL);
  LL_TIM_SetTriggerOutput(TIM2, LL_TIM_TRGO_RESET);
  LL_TIM_DisableMasterSlaveMode(TIM2);
  /* USER CODE BEGIN TIM2_Init 2 */
  LL_TIM_ClearFlag_UPDATE(TIM2);
  /* USER CODE END TIM2_Init 2 */
}

static void MX_TIM3_Init(void) {

  LL_TIM_InitTypeDef TIM_InitStruct = {0};
  LL_TIM_OC_InitTypeDef TIM_OC_InitStruct = {0};

  LL_GPIO_InitTypeDef GPIO_InitStruct = {0};

  /* Peripheral clock enable */
  LL_APB1_GRP1_EnableClock(LL_APB1_GRP1_PERIPH_TIM3);

  TIM_InitStruct.Prescaler = 0;
  TIM_InitStruct.CounterMode = LL_TIM_COUNTERMODE_UP;
  TIM_InitStruct.Autoreload = 65535;
  TIM_InitStruct.ClockDivision = LL_TIM_CLOCKDIVISION_DIV1;
  LL_TIM_Init(TIM3, &TIM_InitStruct);
  LL_TIM_DisableARRPreload(TIM3);
  LL_TIM_SetClockSource(TIM3, LL_TIM_CLOCKSOURCE_INTERNAL);
  TIM_OC_InitStruct.OCMode = LL_TIM_OCMODE_FORCED_ACTIVE;
  TIM_OC_InitStruct.OCState = LL_TIM_OCSTATE_DISABLE;
  TIM_OC_InitStruct.OCNState = LL_TIM_OCSTATE_DISABLE;
  TIM_OC_InitStruct.CompareValue = 0;
  TIM_OC_InitStruct.OCPolarity = LL_TIM_OCPOLARITY_HIGH;
  LL_TIM_OC_Init(TIM3, LL_TIM_CHANNEL_CH1, &TIM_OC_InitStruct);
  LL_TIM_OC_DisableFast(TIM3, LL_TIM_CHANNEL_CH1);
  LL_TIM_SetTriggerOutput(TIM3, LL_TIM_TRGO_ENABLE);
  LL_TIM_EnableMasterSlaveMode(TIM3);
  LL_AHB1_GRP1_EnableClock(LL_AHB1_GRP1_PERIPH_GPIOA);
  /**TIM3 GPIO Configuration
  PA6   ------> TIM3_CH1
  */
  GPIO_InitStruct.Pin = LL_GPIO_PIN_6;
  GPIO_InitStruct.Mode = LL_GPIO_MODE_ALTERNATE;
  GPIO_InitStruct.Speed = LL_GPIO_SPEED_FREQ_LOW;
  GPIO_InitStruct.OutputType = LL_GPIO_OUTPUT_PUSHPULL;
  GPIO_InitStruct.Pull = LL_GPIO_PULL_NO;
  GPIO_InitStruct.Alternate = LL_GPIO_AF_2;
  LL_GPIO_Init(GPIOA, &GPIO_InitStruct);
}

static void MX_TIM5_Init(void) {

  LL_TIM_InitTypeDef TIM_InitStruct = {0};

  /* Peripheral clock enable */
  LL_APB1_GRP1_EnableClock(LL_APB1_GRP1_PERIPH_TIM5);

  /* TIM5 interrupt Init */
  NVIC_SetPriority(TIM5_IRQn,
                   NVIC_EncodePriority(NVIC_GetPriorityGrouping(), 15, 0));
  NVIC_EnableIRQ(TIM5_IRQn);

  TIM_InitStruct.Prescaler = 0;
  TIM_InitStruct.CounterMode = LL_TIM_COUNTERMODE_UP;
  TIM_InitStruct.Autoreload = 4294967295;
  TIM_InitStruct.ClockDivision = LL_TIM_CLOCKDIVISION_DIV1;
  LL_TIM_Init(TIM5, &TIM_InitStruct);
  LL_TIM_DisableARRPreload(TIM5);
  LL_TIM_SetClockSource(TIM5, LL_TIM_CLOCKSOURCE_INTERNAL);
  LL_TIM_SetTriggerOutput(TIM5, LL_TIM_TRGO_RESET);
  LL_TIM_DisableMasterSlaveMode(TIM5);
}

static void MX_TIM8_Init(void) {

  LL_TIM_InitTypeDef TIM_InitStruct = {0};

  LL_GPIO_InitTypeDef GPIO_InitStruct = {0};

  /* Peripheral clock enable */
  LL_APB2_GRP1_EnableClock(LL_APB2_GRP1_PERIPH_TIM8);

  LL_AHB1_GRP1_EnableClock(LL_AHB1_GRP1_PERIPH_GPIOC);
  /**TIM8 GPIO Configuration
  PC6   ------> TIM8_CH1
  PC8   ------> TIM8_CH3
  PC9   ------> TIM8_CH4
  */
  GPIO_InitStruct.Pin = LL_GPIO_PIN_6;
  GPIO_InitStruct.Mode = LL_GPIO_MODE_ALTERNATE;
  GPIO_InitStruct.Speed = LL_GPIO_SPEED_FREQ_VERY_HIGH;
  GPIO_InitStruct.OutputType = LL_GPIO_OUTPUT_PUSHPULL;
  GPIO_InitStruct.Pull = LL_GPIO_PULL_NO;
  GPIO_InitStruct.Alternate = LL_GPIO_AF_3;
  LL_GPIO_Init(GPIOC, &GPIO_InitStruct);

  GPIO_InitStruct.Pin = LL_GPIO_PIN_8;
  GPIO_InitStruct.Mode = LL_GPIO_MODE_ALTERNATE;
  GPIO_InitStruct.Speed = LL_GPIO_SPEED_FREQ_VERY_HIGH;
  GPIO_InitStruct.OutputType = LL_GPIO_OUTPUT_PUSHPULL;
  GPIO_InitStruct.Pull = LL_GPIO_PULL_NO;
  GPIO_InitStruct.Alternate = LL_GPIO_AF_3;
  LL_GPIO_Init(GPIOC, &GPIO_InitStruct);

  GPIO_InitStruct.Pin = LL_GPIO_PIN_9;
  GPIO_InitStruct.Mode = LL_GPIO_MODE_ALTERNATE;
  GPIO_InitStruct.Speed = LL_GPIO_SPEED_FREQ_VERY_HIGH;
  GPIO_InitStruct.OutputType = LL_GPIO_OUTPUT_PUSHPULL;
  GPIO_InitStruct.Pull = LL_GPIO_PULL_NO;
  GPIO_InitStruct.Alternate = LL_GPIO_AF_3;
  LL_GPIO_Init(GPIOC, &GPIO_InitStruct);

  /* TIM8 DMA Init */

  /* TIM8_CH1 Init */
  LL_DMA_SetChannelSelection(DMA2, LL_DMA_STREAM_2, LL_DMA_CHANNEL_7);

  LL_DMA_SetDataTransferDirection(DMA2, LL_DMA_STREAM_2,
                                  LL_DMA_DIRECTION_PERIPH_TO_MEMORY);

  LL_DMA_SetStreamPriorityLevel(DMA2, LL_DMA_STREAM_2, LL_DMA_PRIORITY_HIGH);

  LL_DMA_SetMode(DMA2, LL_DMA_STREAM_2, LL_DMA_MODE_CIRCULAR);

  LL_DMA_SetPeriphIncMode(DMA2, LL_DMA_STREAM_2, LL_DMA_PERIPH_NOINCREMENT);

  LL_DMA_SetMemoryIncMode(DMA2, LL_DMA_STREAM_2, LL_DMA_MEMORY_INCREMENT);

  LL_DMA_SetPeriphSize(DMA2, LL_DMA_STREAM_2, LL_DMA_PDATAALIGN_HALFWORD);

  LL_DMA_SetMemorySize(DMA2, LL_DMA_STREAM_2, LL_DMA_MDATAALIGN_HALFWORD);

  LL_DMA_DisableFifoMode(DMA2, LL_DMA_STREAM_2);

  /* TIM8_CH2 Init */
  LL_DMA_SetChannelSelection(DMA2, LL_DMA_STREAM_3, LL_DMA_CHANNEL_7);

  LL_DMA_SetDataTransferDirection(DMA2, LL_DMA_STREAM_3,
                                  LL_DMA_DIRECTION_PERIPH_TO_MEMORY);

  LL_DMA_SetStreamPriorityLevel(DMA2, LL_DMA_STREAM_3, LL_DMA_PRIORITY_HIGH);

  LL_DMA_SetMode(DMA2, LL_DMA_STREAM_3, LL_DMA_MODE_CIRCULAR);

  LL_DMA_SetPeriphIncMode(DMA2, LL_DMA_STREAM_3, LL_DMA_PERIPH_NOINCREMENT);

  LL_DMA_SetMemoryIncMode(DMA2, LL_DMA_STREAM_3, LL_DMA_MEMORY_INCREMENT);

  LL_DMA_SetPeriphSize(DMA2, LL_DMA_STREAM_3, LL_DMA_PDATAALIGN_HALFWORD);

  LL_DMA_SetMemorySize(DMA2, LL_DMA_STREAM_3, LL_DMA_MDATAALIGN_HALFWORD);

  LL_DMA_DisableFifoMode(DMA2, LL_DMA_STREAM_3);

  /* TIM8_CH3 Init */
  LL_DMA_SetChannelSelection(DMA2, LL_DMA_STREAM_4, LL_DMA_CHANNEL_7);

  LL_DMA_SetDataTransferDirection(DMA2, LL_DMA_STREAM_4,
                                  LL_DMA_DIRECTION_PERIPH_TO_MEMORY);

  LL_DMA_SetStreamPriorityLevel(DMA2, LL_DMA_STREAM_4, LL_DMA_PRIORITY_HIGH);

  LL_DMA_SetMode(DMA2, LL_DMA_STREAM_4, LL_DMA_MODE_CIRCULAR);

  LL_DMA_SetPeriphIncMode(DMA2, LL_DMA_STREAM_4, LL_DMA_PERIPH_NOINCREMENT);

  LL_DMA_SetMemoryIncMode(DMA2, LL_DMA_STREAM_4, LL_DMA_MEMORY_INCREMENT);

  LL_DMA_SetPeriphSize(DMA2, LL_DMA_STREAM_4, LL_DMA_PDATAALIGN_HALFWORD);

  LL_DMA_SetMemorySize(DMA2, LL_DMA_STREAM_4, LL_DMA_MDATAALIGN_HALFWORD);

  LL_DMA_DisableFifoMode(DMA2, LL_DMA_STREAM_4);

  /* TIM8_CH4_TRIG_COM Init */
  LL_DMA_SetChannelSelection(DMA2, LL_DMA_STREAM_7, LL_DMA_CHANNEL_7);

  LL_DMA_SetDataTransferDirection(DMA2, LL_DMA_STREAM_7,
                                  LL_DMA_DIRECTION_PERIPH_TO_MEMORY);

  LL_DMA_SetStreamPriorityLevel(DMA2, LL_DMA_STREAM_7, LL_DMA_PRIORITY_HIGH);

  LL_DMA_SetMode(DMA2, LL_DMA_STREAM_7, LL_DMA_MODE_CIRCULAR);

  LL_DMA_SetPeriphIncMode(DMA2, LL_DMA_STREAM_7, LL_DMA_PERIPH_NOINCREMENT);

  LL_DMA_SetMemoryIncMode(DMA2, LL_DMA_STREAM_7, LL_DMA_MEMORY_INCREMENT);

  LL_DMA_SetPeriphSize(DMA2, LL_DMA_STREAM_7, LL_DMA_PDATAALIGN_HALFWORD);

  LL_DMA_SetMemorySize(DMA2, LL_DMA_STREAM_7, LL_DMA_MDATAALIGN_HALFWORD);

  LL_DMA_DisableFifoMode(DMA2, LL_DMA_STREAM_7);

  TIM_InitStruct.Prescaler = 0;
  TIM_InitStruct.CounterMode = LL_TIM_COUNTERMODE_UP;
  TIM_InitStruct.Autoreload = 65535;
  TIM_InitStruct.ClockDivision = LL_TIM_CLOCKDIVISION_DIV1;
  TIM_InitStruct.RepetitionCounter = 0;
  LL_TIM_Init(TIM8, &TIM_InitStruct);
  LL_TIM_DisableARRPreload(TIM8);
  LL_TIM_SetClockSource(TIM8, LL_TIM_CLOCKSOURCE_INTERNAL);
  LL_TIM_SetTriggerInput(TIM8, LL_TIM_TS_TI1FP1);
  LL_TIM_SetSlaveMode(TIM8, LL_TIM_SLAVEMODE_RESET);
  LL_TIM_IC_SetFilter(TIM8, LL_TIM_CHANNEL_CH1, LL_TIM_IC_FILTER_FDIV1);
  LL_TIM_IC_SetPolarity(TIM8, LL_TIM_CHANNEL_CH1, LL_TIM_IC_POLARITY_RISING);
  LL_TIM_DisableIT_TRIG(TIM8);
  LL_TIM_DisableDMAReq_TRIG(TIM8);
  LL_TIM_SetTriggerOutput(TIM8, LL_TIM_TRGO_RESET);
  LL_TIM_SetTriggerOutput2(TIM8, LL_TIM_TRGO2_RESET);
  LL_TIM_DisableMasterSlaveMode(TIM8);
  LL_TIM_IC_SetActiveInput(TIM8, LL_TIM_CHANNEL_CH1,
                           LL_TIM_ACTIVEINPUT_DIRECTTI);
  LL_TIM_IC_SetPrescaler(TIM8, LL_TIM_CHANNEL_CH1, LL_TIM_ICPSC_DIV1);
  LL_TIM_IC_SetFilter(TIM8, LL_TIM_CHANNEL_CH1, LL_TIM_IC_FILTER_FDIV16_N5);
  LL_TIM_IC_SetActiveInput(TIM8, LL_TIM_CHANNEL_CH2,
                           LL_TIM_ACTIVEINPUT_INDIRECTTI);
  LL_TIM_IC_SetPrescaler(TIM8, LL_TIM_CHANNEL_CH2, LL_TIM_ICPSC_DIV1);
  LL_TIM_IC_SetFilter(TIM8, LL_TIM_CHANNEL_CH2, LL_TIM_IC_FILTER_FDIV1);
  LL_TIM_IC_SetPolarity(TIM8, LL_TIM_CHANNEL_CH2, LL_TIM_IC_POLARITY_FALLING);
  LL_TIM_IC_SetActiveInput(TIM8, LL_TIM_CHANNEL_CH3,
                           LL_TIM_ACTIVEINPUT_DIRECTTI);
  LL_TIM_IC_SetPrescaler(TIM8, LL_TIM_CHANNEL_CH3, LL_TIM_ICPSC_DIV1);
  LL_TIM_IC_SetFilter(TIM8, LL_TIM_CHANNEL_CH3, LL_TIM_IC_FILTER_FDIV16_N5);
  LL_TIM_IC_SetPolarity(TIM8, LL_TIM_CHANNEL_CH3, LL_TIM_IC_POLARITY_FALLING);
  LL_TIM_IC_SetActiveInput(TIM8, LL_TIM_CHANNEL_CH4,
                           LL_TIM_ACTIVEINPUT_DIRECTTI);
  LL_TIM_IC_SetPrescaler(TIM8, LL_TIM_CHANNEL_CH4, LL_TIM_ICPSC_DIV1);
  LL_TIM_IC_SetFilter(TIM8, LL_TIM_CHANNEL_CH4, LL_TIM_IC_FILTER_FDIV16_N5);
  LL_TIM_IC_SetPolarity(TIM8, LL_TIM_CHANNEL_CH4, LL_TIM_IC_POLARITY_FALLING);
  /* USER CODE BEGIN TIM8_Init 2 */
  LL_DMA_SetDataLength(DMA2, LL_DMA_STREAM_2, 1);
  LL_DMA_ConfigAddresses(
      DMA2, LL_DMA_STREAM_2, (uint32_t)&TIM8->CCR1, (uint32_t)&vacs[0],
      LL_DMA_GetDataTransferDirection(DMA2, LL_DMA_STREAM_2));
  LL_DMA_EnableStream(DMA2, LL_DMA_STREAM_2);

  /**/
  LL_DMA_SetDataLength(DMA2, LL_DMA_STREAM_3, 1);
  LL_DMA_ConfigAddresses(
      DMA2, LL_DMA_STREAM_3, (uint32_t)&TIM8->CCR2, (uint32_t)&vacs[1],
      LL_DMA_GetDataTransferDirection(DMA2, LL_DMA_STREAM_3));
  LL_DMA_EnableStream(DMA2, LL_DMA_STREAM_3);
  /**/
  LL_DMA_SetDataLength(DMA2, LL_DMA_STREAM_4, 1);
  LL_DMA_ConfigAddresses(
      DMA2, LL_DMA_STREAM_4, (uint32_t)&TIM8->CCR3, (uint32_t)&vacs[2],
      LL_DMA_GetDataTransferDirection(DMA2, LL_DMA_STREAM_4));
  LL_DMA_EnableStream(DMA2, LL_DMA_STREAM_4);
  /**/
  LL_DMA_SetDataLength(DMA2, LL_DMA_STREAM_7, 1);
  LL_DMA_ConfigAddresses(
      DMA2, LL_DMA_STREAM_7, (uint32_t)&TIM8->CCR4, (uint32_t)&vacs[3],
      LL_DMA_GetDataTransferDirection(DMA2, LL_DMA_STREAM_7));
  LL_DMA_EnableStream(DMA2, LL_DMA_STREAM_7);
  /**/
  LL_TIM_EnableDMAReq_CC1(TIM8);
  LL_TIM_EnableDMAReq_CC2(TIM8);
  LL_TIM_EnableDMAReq_CC3(TIM8);
  LL_TIM_EnableDMAReq_CC4(TIM8);
  /* USER CODE END TIM8_Init 2 */
}

static void MX_TIM11_Init(void) {

  LL_TIM_InitTypeDef TIM_InitStruct = {0};

  /* Peripheral clock enable */
  LL_APB2_GRP1_EnableClock(LL_APB2_GRP1_PERIPH_TIM11);

  /* TIM11 interrupt Init */
  NVIC_SetPriority(TIM1_TRG_COM_TIM11_IRQn,
                   NVIC_EncodePriority(NVIC_GetPriorityGrouping(), 0, 0));
  NVIC_EnableIRQ(TIM1_TRG_COM_TIM11_IRQn);

  TIM_InitStruct.Prescaler = 0;
  TIM_InitStruct.CounterMode = LL_TIM_COUNTERMODE_UP;
  TIM_InitStruct.Autoreload = 65535;
  TIM_InitStruct.ClockDivision = LL_TIM_CLOCKDIVISION_DIV1;
  LL_TIM_Init(TIM11, &TIM_InitStruct);
  LL_TIM_DisableARRPreload(TIM11);
}

static void MX_USART3_UART_Init(void) {

  LL_USART_InitTypeDef USART_InitStruct = {0};

  LL_GPIO_InitTypeDef GPIO_InitStruct = {0};

  LL_RCC_SetUSARTClockSource(LL_RCC_USART3_CLKSOURCE_PCLK1);

  /* Peripheral clock enable */
  LL_APB1_GRP1_EnableClock(LL_APB1_GRP1_PERIPH_USART3);

  LL_AHB1_GRP1_EnableClock(LL_AHB1_GRP1_PERIPH_GPIOD);
  /**USART3 GPIO Configuration
  PD8   ------> USART3_TX
  PD9   ------> USART3_RX
  */
  GPIO_InitStruct.Pin = STLK_RX_Pin;
  GPIO_InitStruct.Mode = LL_GPIO_MODE_ALTERNATE;
  GPIO_InitStruct.Speed = LL_GPIO_SPEED_FREQ_VERY_HIGH;
  GPIO_InitStruct.OutputType = LL_GPIO_OUTPUT_PUSHPULL;
  GPIO_InitStruct.Pull = LL_GPIO_PULL_NO;
  GPIO_InitStruct.Alternate = LL_GPIO_AF_7;
  LL_GPIO_Init(STLK_RX_GPIO_Port, &GPIO_InitStruct);

  GPIO_InitStruct.Pin = STLK_TX_Pin;
  GPIO_InitStruct.Mode = LL_GPIO_MODE_ALTERNATE;
  GPIO_InitStruct.Speed = LL_GPIO_SPEED_FREQ_VERY_HIGH;
  GPIO_InitStruct.OutputType = LL_GPIO_OUTPUT_PUSHPULL;
  GPIO_InitStruct.Pull = LL_GPIO_PULL_NO;
  GPIO_InitStruct.Alternate = LL_GPIO_AF_7;
  LL_GPIO_Init(STLK_TX_GPIO_Port, &GPIO_InitStruct);

  USART_InitStruct.BaudRate = 115200;
  USART_InitStruct.DataWidth = LL_USART_DATAWIDTH_8B;
  USART_InitStruct.StopBits = LL_USART_STOPBITS_1;
  USART_InitStruct.Parity = LL_USART_PARITY_NONE;
  USART_InitStruct.TransferDirection = LL_USART_DIRECTION_TX_RX;
  USART_InitStruct.HardwareFlowControl = LL_USART_HWCONTROL_NONE;
  USART_InitStruct.OverSampling = LL_USART_OVERSAMPLING_16;
  LL_USART_Init(USART3, &USART_InitStruct);
  LL_USART_ConfigAsyncMode(USART3);
  LL_USART_Enable(USART3);
}

static void MX_DMA_Init(void) {

  /* Init with LL driver */
  /* DMA controller clock enable */
  LL_AHB1_GRP1_EnableClock(LL_AHB1_GRP1_PERIPH_DMA2);

  /* DMA interrupt init */
  /* DMA2_Stream0_IRQn interrupt configuration */
  NVIC_SetPriority(DMA2_Stream0_IRQn,
                   NVIC_EncodePriority(NVIC_GetPriorityGrouping(), 6, 0));
  NVIC_EnableIRQ(DMA2_Stream0_IRQn);
  /* DMA2_Stream1_IRQn interrupt configuration */
  NVIC_SetPriority(DMA2_Stream1_IRQn,
                   NVIC_EncodePriority(NVIC_GetPriorityGrouping(), 6, 0));
  NVIC_EnableIRQ(DMA2_Stream1_IRQn);
  /* DMA2_Stream2_IRQn interrupt configuration */
  NVIC_SetPriority(DMA2_Stream2_IRQn,
                   NVIC_EncodePriority(NVIC_GetPriorityGrouping(), 6, 0));
  NVIC_EnableIRQ(DMA2_Stream2_IRQn);
  /* DMA2_Stream3_IRQn interrupt configuration */
  NVIC_SetPriority(DMA2_Stream3_IRQn,
                   NVIC_EncodePriority(NVIC_GetPriorityGrouping(), 6, 0));
  NVIC_EnableIRQ(DMA2_Stream3_IRQn);
  /* DMA2_Stream4_IRQn interrupt configuration */
  NVIC_SetPriority(DMA2_Stream4_IRQn,
                   NVIC_EncodePriority(NVIC_GetPriorityGrouping(), 6, 0));
  NVIC_EnableIRQ(DMA2_Stream4_IRQn);
  /* DMA2_Stream7_IRQn interrupt configuration */
  NVIC_SetPriority(DMA2_Stream7_IRQn,
                   NVIC_EncodePriority(NVIC_GetPriorityGrouping(), 6, 0));
  NVIC_EnableIRQ(DMA2_Stream7_IRQn);
}

static void MX_GPIO_Init(void) {
  LL_EXTI_InitTypeDef EXTI_InitStruct = {0};
  LL_GPIO_InitTypeDef GPIO_InitStruct = {0};

  /* GPIO Ports Clock Enable */
  LL_AHB1_GRP1_EnableClock(LL_AHB1_GRP1_PERIPH_GPIOC);
  LL_AHB1_GRP1_EnableClock(LL_AHB1_GRP1_PERIPH_GPIOF);
  LL_AHB1_GRP1_EnableClock(LL_AHB1_GRP1_PERIPH_GPIOH);
  LL_AHB1_GRP1_EnableClock(LL_AHB1_GRP1_PERIPH_GPIOA);
  LL_AHB1_GRP1_EnableClock(LL_AHB1_GRP1_PERIPH_GPIOB);
  LL_AHB1_GRP1_EnableClock(LL_AHB1_GRP1_PERIPH_GPIOE);
  LL_AHB1_GRP1_EnableClock(LL_AHB1_GRP1_PERIPH_GPIOD);
  LL_AHB1_GRP1_EnableClock(LL_AHB1_GRP1_PERIPH_GPIOG);

  /**/
  LL_GPIO_ResetOutputPin(CAL_GPIO_Port, CAL_Pin);

  /**/
  LL_GPIO_ResetOutputPin(LD1_GPIO_Port, LD1_Pin);

  /**/
  LL_GPIO_ResetOutputPin(LD3_GPIO_Port, LD3_Pin);

  /**/
  LL_GPIO_ResetOutputPin(USB_PowerSwitchOn_GPIO_Port, USB_PowerSwitchOn_Pin);

  /**/
  LL_GPIO_ResetOutputPin(LD2_GPIO_Port, LD2_Pin);

  /**/
  LL_SYSCFG_SetEXTISource(LL_SYSCFG_EXTI_PORTC, LL_SYSCFG_EXTI_LINE13);

  /**/
  EXTI_InitStruct.Line_0_31 = LL_EXTI_LINE_13;
  EXTI_InitStruct.LineCommand = ENABLE;
  EXTI_InitStruct.Mode = LL_EXTI_MODE_IT;
  EXTI_InitStruct.Trigger = LL_EXTI_TRIGGER_RISING;
  LL_EXTI_Init(&EXTI_InitStruct);

  /**/
  LL_GPIO_SetPinPull(USER_Btn_GPIO_Port, USER_Btn_Pin, LL_GPIO_PULL_NO);

  /**/
  LL_GPIO_SetPinMode(USER_Btn_GPIO_Port, USER_Btn_Pin, LL_GPIO_MODE_INPUT);

  /**/
  GPIO_InitStruct.Pin = CAL_Pin;
  GPIO_InitStruct.Mode = LL_GPIO_MODE_OUTPUT;
  GPIO_InitStruct.Speed = LL_GPIO_SPEED_FREQ_VERY_HIGH;
  GPIO_InitStruct.OutputType = LL_GPIO_OUTPUT_PUSHPULL;
  GPIO_InitStruct.Pull = LL_GPIO_PULL_NO;
  LL_GPIO_Init(CAL_GPIO_Port, &GPIO_InitStruct);

  /**/
  GPIO_InitStruct.Pin = RMII_MDC_Pin;
  GPIO_InitStruct.Mode = LL_GPIO_MODE_ALTERNATE;
  GPIO_InitStruct.Speed = LL_GPIO_SPEED_FREQ_VERY_HIGH;
  GPIO_InitStruct.OutputType = LL_GPIO_OUTPUT_PUSHPULL;
  GPIO_InitStruct.Pull = LL_GPIO_PULL_NO;
  GPIO_InitStruct.Alternate = LL_GPIO_AF_11;
  LL_GPIO_Init(RMII_MDC_GPIO_Port, &GPIO_InitStruct);

  /**/
  GPIO_InitStruct.Pin = RMII_REF_CLK_Pin;
  GPIO_InitStruct.Mode = LL_GPIO_MODE_ALTERNATE;
  GPIO_InitStruct.Speed = LL_GPIO_SPEED_FREQ_VERY_HIGH;
  GPIO_InitStruct.OutputType = LL_GPIO_OUTPUT_PUSHPULL;
  GPIO_InitStruct.Pull = LL_GPIO_PULL_NO;
  GPIO_InitStruct.Alternate = LL_GPIO_AF_11;
  LL_GPIO_Init(RMII_REF_CLK_GPIO_Port, &GPIO_InitStruct);

  /**/
  GPIO_InitStruct.Pin = RMII_MDIO_Pin;
  GPIO_InitStruct.Mode = LL_GPIO_MODE_ALTERNATE;
  GPIO_InitStruct.Speed = LL_GPIO_SPEED_FREQ_VERY_HIGH;
  GPIO_InitStruct.OutputType = LL_GPIO_OUTPUT_PUSHPULL;
  GPIO_InitStruct.Pull = LL_GPIO_PULL_NO;
  GPIO_InitStruct.Alternate = LL_GPIO_AF_11;
  LL_GPIO_Init(RMII_MDIO_GPIO_Port, &GPIO_InitStruct);

  /**/
  GPIO_InitStruct.Pin = RMII_CRS_DV_Pin;
  GPIO_InitStruct.Mode = LL_GPIO_MODE_ALTERNATE;
  GPIO_InitStruct.Speed = LL_GPIO_SPEED_FREQ_VERY_HIGH;
  GPIO_InitStruct.OutputType = LL_GPIO_OUTPUT_PUSHPULL;
  GPIO_InitStruct.Pull = LL_GPIO_PULL_NO;
  GPIO_InitStruct.Alternate = LL_GPIO_AF_11;
  LL_GPIO_Init(RMII_CRS_DV_GPIO_Port, &GPIO_InitStruct);

  /**/
  GPIO_InitStruct.Pin = RMII_RXD0_Pin;
  GPIO_InitStruct.Mode = LL_GPIO_MODE_ALTERNATE;
  GPIO_InitStruct.Speed = LL_GPIO_SPEED_FREQ_VERY_HIGH;
  GPIO_InitStruct.OutputType = LL_GPIO_OUTPUT_PUSHPULL;
  GPIO_InitStruct.Pull = LL_GPIO_PULL_NO;
  GPIO_InitStruct.Alternate = LL_GPIO_AF_11;
  LL_GPIO_Init(RMII_RXD0_GPIO_Port, &GPIO_InitStruct);

  /**/
  GPIO_InitStruct.Pin = RMII_RXD1_Pin;
  GPIO_InitStruct.Mode = LL_GPIO_MODE_ALTERNATE;
  GPIO_InitStruct.Speed = LL_GPIO_SPEED_FREQ_VERY_HIGH;
  GPIO_InitStruct.OutputType = LL_GPIO_OUTPUT_PUSHPULL;
  GPIO_InitStruct.Pull = LL_GPIO_PULL_NO;
  GPIO_InitStruct.Alternate = LL_GPIO_AF_11;
  LL_GPIO_Init(RMII_RXD1_GPIO_Port, &GPIO_InitStruct);

  /**/
  GPIO_InitStruct.Pin = LD1_Pin;
  GPIO_InitStruct.Mode = LL_GPIO_MODE_OUTPUT;
  GPIO_InitStruct.Speed = LL_GPIO_SPEED_FREQ_LOW;
  GPIO_InitStruct.OutputType = LL_GPIO_OUTPUT_PUSHPULL;
  GPIO_InitStruct.Pull = LL_GPIO_PULL_NO;
  LL_GPIO_Init(LD1_GPIO_Port, &GPIO_InitStruct);

  /**/
  GPIO_InitStruct.Pin = RMII_TXD1_Pin;
  GPIO_InitStruct.Mode = LL_GPIO_MODE_ALTERNATE;
  GPIO_InitStruct.Speed = LL_GPIO_SPEED_FREQ_VERY_HIGH;
  GPIO_InitStruct.OutputType = LL_GPIO_OUTPUT_PUSHPULL;
  GPIO_InitStruct.Pull = LL_GPIO_PULL_NO;
  GPIO_InitStruct.Alternate = LL_GPIO_AF_11;
  LL_GPIO_Init(RMII_TXD1_GPIO_Port, &GPIO_InitStruct);

  /**/
  GPIO_InitStruct.Pin = LD3_Pin;
  GPIO_InitStruct.Mode = LL_GPIO_MODE_OUTPUT;
  GPIO_InitStruct.Speed = LL_GPIO_SPEED_FREQ_LOW;
  GPIO_InitStruct.OutputType = LL_GPIO_OUTPUT_PUSHPULL;
  GPIO_InitStruct.Pull = LL_GPIO_PULL_NO;
  LL_GPIO_Init(LD3_GPIO_Port, &GPIO_InitStruct);

  /**/
  GPIO_InitStruct.Pin = USB_PowerSwitchOn_Pin;
  GPIO_InitStruct.Mode = LL_GPIO_MODE_OUTPUT;
  GPIO_InitStruct.Speed = LL_GPIO_SPEED_FREQ_LOW;
  GPIO_InitStruct.OutputType = LL_GPIO_OUTPUT_PUSHPULL;
  GPIO_InitStruct.Pull = LL_GPIO_PULL_NO;
  LL_GPIO_Init(USB_PowerSwitchOn_GPIO_Port, &GPIO_InitStruct);

  /**/
  GPIO_InitStruct.Pin = USB_OverCurrent_Pin;
  GPIO_InitStruct.Mode = LL_GPIO_MODE_INPUT;
  GPIO_InitStruct.Pull = LL_GPIO_PULL_NO;
  LL_GPIO_Init(USB_OverCurrent_GPIO_Port, &GPIO_InitStruct);

  /**/
  GPIO_InitStruct.Pin = USB_SOF_Pin;
  GPIO_InitStruct.Mode = LL_GPIO_MODE_ALTERNATE;
  GPIO_InitStruct.Speed = LL_GPIO_SPEED_FREQ_VERY_HIGH;
  GPIO_InitStruct.OutputType = LL_GPIO_OUTPUT_PUSHPULL;
  GPIO_InitStruct.Pull = LL_GPIO_PULL_NO;
  GPIO_InitStruct.Alternate = LL_GPIO_AF_10;
  LL_GPIO_Init(USB_SOF_GPIO_Port, &GPIO_InitStruct);

  /**/
  GPIO_InitStruct.Pin = USB_VBUS_Pin;
  GPIO_InitStruct.Mode = LL_GPIO_MODE_INPUT;
  GPIO_InitStruct.Pull = LL_GPIO_PULL_NO;
  LL_GPIO_Init(USB_VBUS_GPIO_Port, &GPIO_InitStruct);

  /**/
  GPIO_InitStruct.Pin = USB_ID_Pin;
  GPIO_InitStruct.Mode = LL_GPIO_MODE_ALTERNATE;
  GPIO_InitStruct.Speed = LL_GPIO_SPEED_FREQ_VERY_HIGH;
  GPIO_InitStruct.OutputType = LL_GPIO_OUTPUT_PUSHPULL;
  GPIO_InitStruct.Pull = LL_GPIO_PULL_NO;
  GPIO_InitStruct.Alternate = LL_GPIO_AF_10;
  LL_GPIO_Init(USB_ID_GPIO_Port, &GPIO_InitStruct);

  /**/
  GPIO_InitStruct.Pin = USB_DM_Pin;
  GPIO_InitStruct.Mode = LL_GPIO_MODE_ALTERNATE;
  GPIO_InitStruct.Speed = LL_GPIO_SPEED_FREQ_VERY_HIGH;
  GPIO_InitStruct.OutputType = LL_GPIO_OUTPUT_PUSHPULL;
  GPIO_InitStruct.Pull = LL_GPIO_PULL_NO;
  GPIO_InitStruct.Alternate = LL_GPIO_AF_10;
  LL_GPIO_Init(USB_DM_GPIO_Port, &GPIO_InitStruct);

  /**/
  GPIO_InitStruct.Pin = USB_DP_Pin;
  GPIO_InitStruct.Mode = LL_GPIO_MODE_ALTERNATE;
  GPIO_InitStruct.Speed = LL_GPIO_SPEED_FREQ_VERY_HIGH;
  GPIO_InitStruct.OutputType = LL_GPIO_OUTPUT_PUSHPULL;
  GPIO_InitStruct.Pull = LL_GPIO_PULL_NO;
  GPIO_InitStruct.Alternate = LL_GPIO_AF_10;
  LL_GPIO_Init(USB_DP_GPIO_Port, &GPIO_InitStruct);

  /**/
  GPIO_InitStruct.Pin = RMII_TX_EN_Pin;
  GPIO_InitStruct.Mode = LL_GPIO_MODE_ALTERNATE;
  GPIO_InitStruct.Speed = LL_GPIO_SPEED_FREQ_VERY_HIGH;
  GPIO_InitStruct.OutputType = LL_GPIO_OUTPUT_PUSHPULL;
  GPIO_InitStruct.Pull = LL_GPIO_PULL_NO;
  GPIO_InitStruct.Alternate = LL_GPIO_AF_11;
  LL_GPIO_Init(RMII_TX_EN_GPIO_Port, &GPIO_InitStruct);

  /**/
  GPIO_InitStruct.Pin = RMII_TXD0_Pin;
  GPIO_InitStruct.Mode = LL_GPIO_MODE_ALTERNATE;
  GPIO_InitStruct.Speed = LL_GPIO_SPEED_FREQ_VERY_HIGH;
  GPIO_InitStruct.OutputType = LL_GPIO_OUTPUT_PUSHPULL;
  GPIO_InitStruct.Pull = LL_GPIO_PULL_NO;
  GPIO_InitStruct.Alternate = LL_GPIO_AF_11;
  LL_GPIO_Init(RMII_TXD0_GPIO_Port, &GPIO_InitStruct);

  /**/
  GPIO_InitStruct.Pin = LD2_Pin;
  GPIO_InitStruct.Mode = LL_GPIO_MODE_OUTPUT;
  GPIO_InitStruct.Speed = LL_GPIO_SPEED_FREQ_LOW;
  GPIO_InitStruct.OutputType = LL_GPIO_OUTPUT_PUSHPULL;
  GPIO_InitStruct.Pull = LL_GPIO_PULL_NO;
  LL_GPIO_Init(LD2_GPIO_Port, &GPIO_InitStruct);

  /* EXTI interrupt init*/
  NVIC_SetPriority(EXTI15_10_IRQn,
                   NVIC_EncodePriority(NVIC_GetPriorityGrouping(), 15, 0));
  NVIC_EnableIRQ(EXTI15_10_IRQn);

}

/* USER CODE BEGIN 4 */
static void Init_Ctrl(void) {}

/* USER CODE END 4 */

void Error_Handler(void) {
  __disable_irq();
  while (1) {
  }
}

#ifdef USE_FULL_ASSERT
/**
 * @brief  Reports the name of the source file and the source line number
 *         where the assert_param error has occurred.
 * @param  file: pointer to the source file name
 * @param  line: assert_param error line source number
 * @retval None
 */
void assert_failed(uint8_t *file, uint32_t line) {
  /* USER CODE BEGIN 6 */
  /* User can add his own implementation to report the file name and line
     number, ex: printf("Wrong parameters value: file %s on line %d\r\n", file,
     line) */
  /* USER CODE END 6 */
}
#endif /* USE_FULL_ASSERT */
